# ICSSM0_PR1_MII_RT_PR1_MII_RT_G_CFG_REGS_G register map
Vendor: Texas Instruments
Peripheral module from a debugger description file (folder am62x).
Registers are 32-bit, read-only, reset 0x0 unless marked. A register's access mark holds for its fields unless they carry their own. Offsets are as the file gives them; lines under a group give offsets from that group; [hi:lo] are bit positions; {n}, {i} and the like mark numbered series; 'fields as' and 'values as' point back to an identical list; <NAME> marks a mode.

## ICSSM0_PR1_MII_RT_PR1_MII_RT_G_CFG_REGS_G
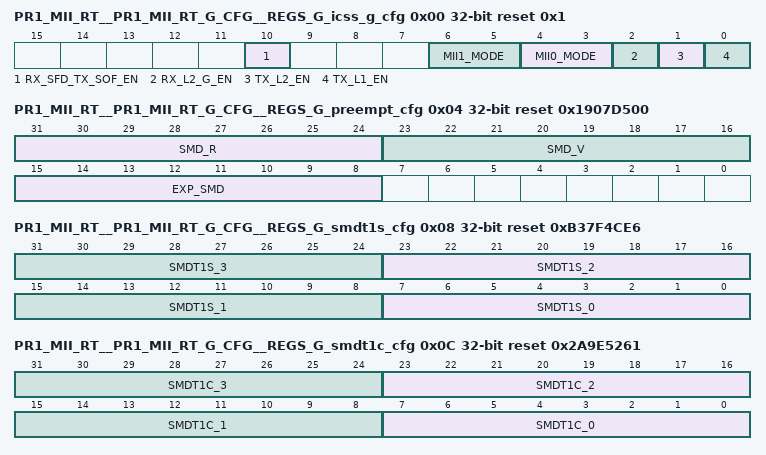
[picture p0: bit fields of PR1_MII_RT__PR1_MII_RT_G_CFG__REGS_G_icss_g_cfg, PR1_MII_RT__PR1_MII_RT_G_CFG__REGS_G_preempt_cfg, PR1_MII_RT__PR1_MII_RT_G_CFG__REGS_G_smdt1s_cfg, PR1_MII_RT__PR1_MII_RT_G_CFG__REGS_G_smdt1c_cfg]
0x00 PR1_MII_RT__PR1_MII_RT_G_CFG__REGS_G_icss_g_cfg rw reset 0x1 — ICSS_G Ethernet Cfg
  [10] RX_SFD_TX_SOF_EN — Enable the remaping of tx_sof to rx_sfd if auto fwd is enable
  [6:5] MII1_MODE — MII1 MODE 0: MII 1: RGMII 2: SGMII
  [4:3] MII0_MODE — MII0 MODE 0: MII 1: RGMII 2: SGMII
  [2] RX_L2_G_EN — Enable the RX L2 G features of filter frags of size TBD and backpressure RX L2 0: Disabled 1: Enabled
  [1] TX_L2_EN — Enable the TX L2 Fifo 0: Disabled 1: Enabled
  [0] TX_L1_EN — Enable the TX L1 Fifo 0: Disabled 1: Enabled
0x04 PR1_MII_RT__PR1_MII_RT_G_CFG__REGS_G_preempt_cfg rw reset 0x1907D500
  [31:24] SMD_R — Response frame TAG
  [23:16] SMD_V — Verification frame TAG
  [15:8] EXP_SMD — None preemptable frame start, or express frame
0x08 PR1_MII_RT__PR1_MII_RT_G_CFG__REGS_G_smdt1s_cfg rw reset 0xB37F4CE6
  [8n+7:8n] SMDT1S_{n} (n=0..3) — SMDT1S{n} pattern
0x0C PR1_MII_RT__PR1_MII_RT_G_CFG__REGS_G_smdt1c_cfg rw reset 0x2A9E5261
  [8n+7:8n] SMDT1C_{n} (n=0..3) — SMDT1C{n} pattern
0x10 PR1_MII_RT__PR1_MII_RT_G_CFG__REGS_G_pool_ptr_cfg rw reset 0x800
  [15:0] MAX_PKT_SIZE — Max Pkt Size, used in pool ptr logic for wrap around
0x14 PR1_MII_RT__PR1_MII_RT_G_CFG__REGS_G_tx_early_eof access not given reset not defined
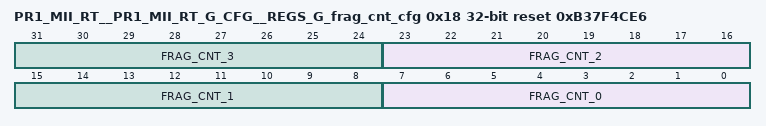
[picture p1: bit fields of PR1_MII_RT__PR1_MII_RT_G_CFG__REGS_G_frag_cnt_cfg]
0x18 PR1_MII_RT__PR1_MII_RT_G_CFG__REGS_G_frag_cnt_cfg rw reset 0xB37F4CE6
  [8n+7:8n] FRAG_CNT_{n} (n=0..3) — FRAG Cnt{n} pattern
{0xD00+4i} PR1_MII_RT__PR1_MII_RT_G_CFG__REGS_G_queue{i} rw (i=0..31)
  [15:0] QUEUE_H_PTR{i} — Queue {i}
{0xE00+4i} PR1_MII_RT__PR1_MII_RT_G_CFG__REGS_G_queue_peek{i} (i=0..15)
  [15:0] QUEUE_H_PEEK_PTR{i} — Queue {i} Peek portal
{0xE40+4i} PR1_MII_RT__PR1_MII_RT_G_CFG__REGS_G_queue_cnt{i} (i=0..31)
  [15:0] QUEUE_CNT_ENTRIES_{i} — Queue Entry Count{i}
0xF40 PR1_MII_RT__PR1_MII_RT_G_CFG__REGS_G_queue_reset rw
  [5:0] RESET_QUEUE_ID
